# A31G12x_series register map
Vendor: ABOV Semiconductor Co., Ltd.; Series: A31G12x_series; File version: 1.0
CPU: CM0PLUS r0p1, little endian, no MPU, no FPU, VTOR, 2 interrupt priority bits
Registers are 32-bit, read-write, reset 0x0 unless marked. A register's access mark holds for its fields unless they carry their own. Offsets are from the block's base; [hi:lo] are bit positions.

## WDT — WATCH-DOG TIMER
Base 0x40001A00
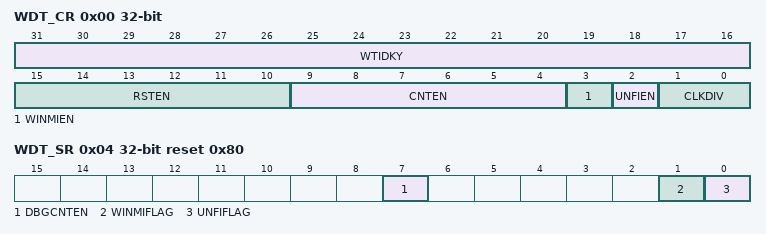
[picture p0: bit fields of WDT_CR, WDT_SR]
0x00 WDT_CR — Watch-dog Timer Control Register
  [31:16] WTIDKY wo — Write Identification Key. On writes, write 0x5A69 to these bits, otherwise the write is ignored.
  [15:10] RSTEN — Watch-dog Timer Reset Enable bits
    37=DISABLE_WDT_RST (Disable watch-dog timer reset); 0=ENABLE_WDT_RST (Enable watch-dog timer reset)
  [9:4] CNTEN — Watch-dog Timer Counter Enable bits
    26=DISABLE_WDT_CNT (Disable watch-dog timer counter); 0=ENABLE_WDT_CNT (Enable watch-dog timer counter)
  [3] WINMIEN — Watch-dog Timer Window Match Interrupt Enable bit
    0=DISABLE_WDT_WDM_INT (Disable window data match interrupt); 1=ENABLE_WDT_WDM_INT (Enable window data match interrupt)
  [2] UNFIEN — Watch-dog Timer Underflow Interrupt Enable bit
    0=DISABLE_WDT_UDF_INT (Disable watch-dog timer underflow interrupt); 1=ENABLE_WDT_UDF_INT (Enable watch-dog timer underflow interrupt)
  [1:0] CLKDIV — Watch-dog Timer Clock Divider bits, The clock which is selected by PPCLKSR[0]
    0=WDT_CLK_DIVIDER_4 (fWDT/4); 1=WDT_CLK_DIVIDER_16 (fWDT/16); 2=WDT_CLK_DIVIDER_64 (fWDT/64); 3=WDT_CLK_DIVIDER_256 (fWDT/256)
0x04 WDT_SR reset 0x80 — Watch-dog Timer Status Register
  [7] DBGCNTEN — Watch-dog Timer Counter Enable bit. When the core is halted in the debug mode. Note: This bit is cleared to "0b" only by POR reset.
    0=RUN_CORE_HALTED (The watch-dog timer counter continues even if the core is halted.); 1=STOP_CORE_HALTED (The watch-dog timer counter is stopped when the core is halted.)
  [1] WINMIFLAG — Watch-dog Timer Window Match Interrupt Flag bit
    0=WDT_WDM_IF_CLR (No request occurred); 1=WDT_WDM_IF_SET (Request occurred, This bit is cleared to '0' when write '1'.)
  [0] UNFIFLAG — Watch-dog Timer Underflow Interrupt Flag bit
    0=WDT_UDF_IF_CLR (No request occurred); 1=WDT_UDF_IF_SET (Request occurred, This bit is cleared to '0' when write '1'.)
0x08 WDT_DR reset 0xFFF — Watch-dog Timer Data Register
  [23:0] DATA — Watch-dog Timer Data bits. The range is 0x000000 to 0xFFFFFF.
0x0C WDT_CNT ro reset 0xFFF — Watch-dog Timer Counter Register
  [23:0] CNT — Watch-dog Timer Counter bits.
0x10 WDT_WINDR reset 0x1FFF — Watch-dog Timer Window Data Register (Note: Once any value is written to this window data register, the register can't be changed until a system reset.)
  [23:0] WDATA — Watch-dog Timer Window Data bits. The range is 0x000000 to 0xFFFFFF.
0x14 WDT_CNTR wo — Watch-dog Timer Counter Reload Register
  [7:0] CNTR — Watch-dog Timer Counter Reload bits.
    106=RELOAD_WDTDR (Reload the WDTDR value to watch-dog timer counter and re-start. (Automatically cleared to "0x00" after operation)); 0=UNLOAD_WDTDR (No effect)

## FMC — FLASH MEMORY CONTROLLER
Base 0x40001B00
0x00 FMC_ADR reset 0x5FFFFF80 — Flash Memory Address Register. Note: The LSB-2bits of the target flash address is always considered to "00b".
  [31:0] ADDR — Flash Memory Address Pointer. This register is reset to 0x5FFFFF80 immediately after one time operation.
0x04 FMC_IDR1 — Flash Memory Identification Register 1
  [31:0] ID0 — Flash Memory Identification 0
0x08 FMC_IDR2 — Flash Memory Identification Register 2. Notes: 1. The FMIDR1/2 registers are automatically cleared to logic 0x00000000 immediately after one time operation except "flash page buffer reset mode". 2. The FMIDR0/1 registers should be written with correct values in turn. 3. If incorrect values are written to the FMIDR0/1 registers, the registers are cleared to logic 0x00000000.
  [31:0] ID1 — Flash Memory Identification 1
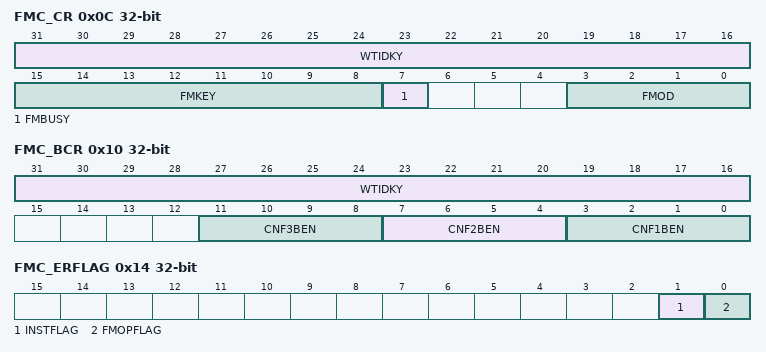
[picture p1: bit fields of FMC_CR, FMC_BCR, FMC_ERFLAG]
0x0C FMC_CR — Flash Memory Control Register. Notes: 1. During a flash memory operation mode, the all interrupts are on disable state regardless of enable bits. 2. The FMKEY[7:0] and FMOD[3:0] bits are automatically cleared to logic "0x00" immediately after one time operation.
  [31:16] WTIDKY wo — Write Identification Key. On writes, write 0x6C93 to these bits, otherwise the write is ignored.
  [15:8] FMKEY — Flash Memory Operation Area Selection bits
  [7] FMBUSY ro — Flash Memory Operation Mode Busy bit
  [3:0] FMOD — Flash Memory Operation Mode Selection bits
0x10 FMC_BCR — Flash Memory Configure Area Bulk Erase Control Register. Note: This register is automatically cleared to logic "0x00" immediately after one time operation.
  [31:16] WTIDKY wo — Write Identification Key. On writes, write 0xC1BE to these bits, otherwise the write is ignored.
  [11:8] CNF3BEN — Configure Option Page 3 Bulk Erase Enable bits.
  [7:4] CNF2BEN — Configure Option Page 2 Bulk Erase Enable bits.
  [3:0] CNF1BEN — Configure Option Page 1 Bulk Erase Enable bits.
0x14 FMC_ERFLAG (reset mask 0x1) — Flash Memory Hard Fault Flag
  [1] INSTFLAG — Don't care
  [0] FMOPFLAG — Error bit of Flash Memory Operation Procedure. This bit is set to logic 1 if there is a wrong procedure for flash memory operation.
0x100 FMC_PAGEBUF wo — Flash Memory Page Buffer Area
